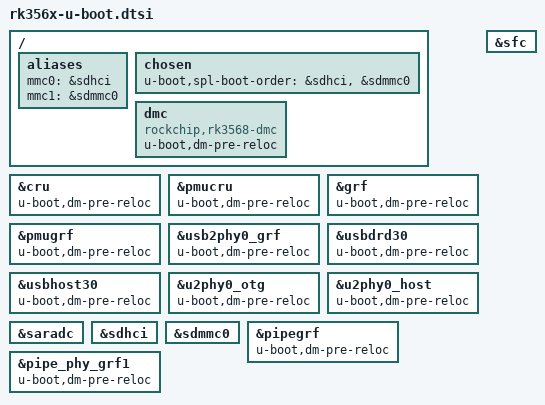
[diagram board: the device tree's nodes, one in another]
// SPDX-License-Identifier: (GPL-2.0+ OR MIT)
/*
 * (C) Copyright 2021 Rockchip Electronics Co., Ltd
 */

#include "rockchip-u-boot.dtsi"

/ {
	aliases {
		mmc0 = &sdhci;
		mmc1 = &sdmmc0;
	};

	chosen {
		u-boot,spl-boot-order = &sdhci, &sdmmc0;
	};

	dmc: dmc {
		compatible = "rockchip,rk3568-dmc";
		u-boot,dm-pre-reloc;
		status = "okay";
	};
};

&cru {
	u-boot,dm-pre-reloc;
	status = "okay";
};

&pmucru {
	u-boot,dm-pre-reloc;
	status = "okay";
};

&grf {
	u-boot,dm-pre-reloc;
	status = "okay";
};

&pmugrf {
	u-boot,dm-pre-reloc;
	status = "okay";
};

&usb2phy0_grf {
	u-boot,dm-pre-reloc;
	status = "okay";
};

&usbdrd30 {
	u-boot,dm-pre-reloc;
	status = "okay";
};

&usbhost30 {
	u-boot,dm-pre-reloc;
	status = "okay";
};

&u2phy0_otg {
	u-boot,dm-pre-reloc;
	status = "okay";
};

&u2phy0_host {
	u-boot,dm-pre-reloc;
	status = "okay";
};

&usb2phy0_grf {
	u-boot,dm-pre-reloc;
	status = "okay";
};

&usbdrd30 {
	u-boot,dm-pre-reloc;
	status = "okay";
};

&usbhost30 {
	u-boot,dm-pre-reloc;
	status = "okay";
};

&u2phy0_otg {
	u-boot,dm-pre-reloc;
	status = "okay";
};

&u2phy0_host {
	u-boot,dm-pre-reloc;
	status = "okay";
};

&saradc {
	u-boot,dm-spl;
	status = "okay";
};

&sdhci {
	u-boot,dm-spl;
	status = "okay";
};

&sdmmc0 {
	u-boot,dm-spl;
	status = "okay";
};

&sfc {
	u-boot,dm-spl;
};

&pipegrf {
	u-boot,dm-pre-reloc;
};

&pipe_phy_grf1{
	u-boot,dm-pre-reloc;
};

&pipegrf {
	u-boot,dm-pre-reloc;
};

&pipe_phy_grf1{
	u-boot,dm-pre-reloc;
};
